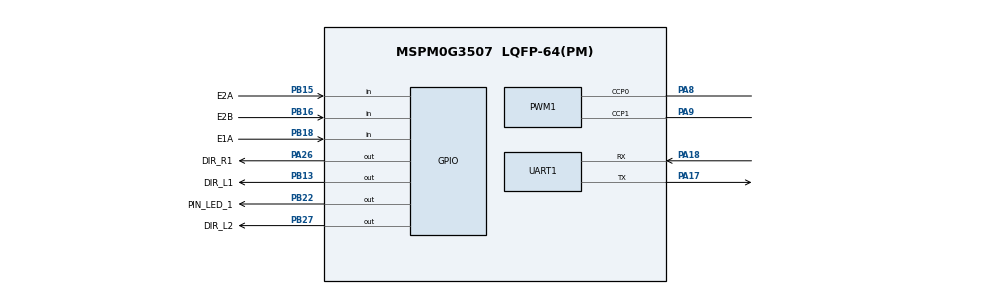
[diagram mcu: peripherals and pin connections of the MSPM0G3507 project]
/**
 * These arguments were used when this file was generated. They will be automatically applied on subsequent loads
 * via the GUI or CLI. Run CLI with '--help' for additional information on how to override these arguments.
 * @cliArgs --device "MSPM0G350X" --part "Default" --package "LQFP-64(PM)" --product "mspm0_sdk@2.05.01.00"
 * @v2CliArgs --device "MSPM0G3507" --package "LQFP-64(PM)" --product "mspm0_sdk@2.05.01.00"
 * @versions {"tool":"1.24.0+4110"}
 */

/**
 * Import the modules used in this configuration.
 */
const GPIO   = scripting.addModule("/ti/driverlib/GPIO", {}, false);
const GPIO1  = GPIO.addInstance();
const GPIO2  = GPIO.addInstance();
const GPIO3  = GPIO.addInstance();
const GPIO4  = GPIO.addInstance();
const GPIO5  = GPIO.addInstance();
const GPIO6  = GPIO.addInstance();
const PWM    = scripting.addModule("/ti/driverlib/PWM", {}, false);
const PWM1   = PWM.addInstance();
const SYSCTL = scripting.addModule("/ti/driverlib/SYSCTL");
const TIMER  = scripting.addModule("/ti/driverlib/TIMER", {}, false);
const TIMER1 = TIMER.addInstance();
const TIMER2 = TIMER.addInstance();
const UART   = scripting.addModule("/ti/driverlib/UART", {}, false);
const UART1  = UART.addInstance();

/**
 * Write custom configuration values to the imported modules.
 */
const divider6       = system.clockTree["PLL_CLK2X_DIV"];
divider6.divideValue = 4;

const divider7       = system.clockTree["PLL_PDIV"];
divider7.divideValue = 2;

const divider9       = system.clockTree["UDIV"];
divider9.divideValue = 2;

const multiplier2         = system.clockTree["PLL_QDIV"];
multiplier2.multiplyValue = 10;

const mux8       = system.clockTree["HSCLKMUX"];
mux8.inputSelect = "HSCLKMUX_SYSPLL2X";

GPIO1.$name                         = "GPIO_DIRS";
GPIO1.associatedPins.create(4);
GPIO1.associatedPins[0].$name       = "DIR_L1";
GPIO1.associatedPins[0].pin.$assign = "PB13";
GPIO1.associatedPins[1].$name       = "DIR_L2";
GPIO1.associatedPins[1].pin.$assign = "PB27";
GPIO1.associatedPins[2].$name       = "DIR_R1";
GPIO1.associatedPins[2].pin.$assign = "PA26";
GPIO1.associatedPins[3].$name       = "PIN_R2";

const Board = scripting.addModule("/ti/driverlib/Board", {}, false);

GPIO2.$name                         = "GPIO_LEDS";
GPIO2.associatedPins[0].$name       = "PIN_LED_1";
GPIO2.associatedPins[0].pin.$assign = "PB22";

GPIO3.$name                              = "GPIO_GREY_SENSOR";
GPIO3.associatedPins.create(7);
GPIO3.associatedPins[0].$name            = "L3";
GPIO3.associatedPins[0].direction        = "INPUT";
GPIO3.associatedPins[0].internalResistor = "PULL_UP";
GPIO3.associatedPins[1].$name            = "L2";
GPIO3.associatedPins[1].direction        = "INPUT";
GPIO3.associatedPins[1].internalResistor = "PULL_UP";
GPIO3.associatedPins[2].$name            = "L1";
GPIO3.associatedPins[2].direction        = "INPUT";
GPIO3.associatedPins[2].internalResistor = "PULL_UP";
GPIO3.associatedPins[3].$name            = "M";
GPIO3.associatedPins[3].direction        = "INPUT";
GPIO3.associatedPins[3].internalResistor = "PULL_UP";
GPIO3.associatedPins[4].$name            = "R1";
GPIO3.associatedPins[4].direction        = "INPUT";
GPIO3.associatedPins[4].internalResistor = "PULL_UP";
GPIO3.associatedPins[5].$name            = "R2";
GPIO3.associatedPins[5].internalResistor = "PULL_UP";
GPIO3.associatedPins[6].$name            = "R3";
GPIO3.associatedPins[6].direction        = "INPUT";
GPIO3.associatedPins[6].internalResistor = "PULL_UP";

GPIO4.$name                               = "ENCODERA";
GPIO4.associatedPins.create(2);
GPIO4.associatedPins[0].direction         = "INPUT";
GPIO4.associatedPins[0].internalResistor  = "PULL_DOWN";
GPIO4.associatedPins[0].interruptEn       = true;
GPIO4.associatedPins[0].interruptPriority = "0";
GPIO4.associatedPins[0].polarity          = "RISE";
GPIO4.associatedPins[0].assignedPort      = "PORTB";
GPIO4.associatedPins[0].assignedPin       = "18";
GPIO4.associatedPins[0].$name             = "E1A";
GPIO4.associatedPins[0].pin.$assign       = "PB18";
GPIO4.associatedPins[1].direction         = "INPUT";
GPIO4.associatedPins[1].internalResistor  = "PULL_DOWN";
GPIO4.associatedPins[1].assignedPort      = "PORTB";
GPIO4.associatedPins[1].assignedPin       = "17";
GPIO4.associatedPins[1].$name             = "E1B";
GPIO4.associatedPins[1].interruptEn       = true;
GPIO4.associatedPins[1].interruptPriority = "0";
GPIO4.associatedPins[1].polarity          = "RISE";

GPIO5.$name                               = "ENCODERB";
GPIO5.associatedPins.create(2);
GPIO5.associatedPins[0].$name             = "E2A";
GPIO5.associatedPins[0].direction         = "INPUT";
GPIO5.associatedPins[0].interruptEn       = true;
GPIO5.associatedPins[0].interruptPriority = "0";
GPIO5.associatedPins[0].polarity          = "RISE";
GPIO5.associatedPins[0].internalResistor  = "PULL_DOWN";
GPIO5.associatedPins[0].assignedPort      = "PORTB";
GPIO5.associatedPins[0].assignedPin       = "15";
GPIO5.associatedPins[0].pin.$assign       = "PB15";
GPIO5.associatedPins[1].$name             = "E2B";
GPIO5.associatedPins[1].direction         = "INPUT";
GPIO5.associatedPins[1].interruptEn       = true;
GPIO5.associatedPins[1].interruptPriority = "0";
GPIO5.associatedPins[1].polarity          = "RISE";
GPIO5.associatedPins[1].internalResistor  = "PULL_DOWN";
GPIO5.associatedPins[1].assignedPort      = "PORTB";
GPIO5.associatedPins[1].assignedPin       = "16";
GPIO5.associatedPins[1].pin.$assign       = "PB16";

GPIO6.$name                               = "KEYS";
GPIO6.associatedPins.create(4);
GPIO6.associatedPins[0].$name             = "KEY1";
GPIO6.associatedPins[0].direction         = "INPUT";
GPIO6.associatedPins[0].interruptEn       = true;
GPIO6.associatedPins[0].interruptPriority = "0";
GPIO6.associatedPins[0].internalResistor  = "PULL_UP";
GPIO6.associatedPins[0].assignedPort      = "PORTB";
GPIO6.associatedPins[0].assignedPin       = "14";
GPIO6.associatedPins[0].polarity          = "RISE_FALL";
GPIO6.associatedPins[1].$name             = "KEY2";
GPIO6.associatedPins[1].direction         = "INPUT";
GPIO6.associatedPins[1].internalResistor  = "PULL_UP";
GPIO6.associatedPins[1].assignedPort      = "PORTB";
GPIO6.associatedPins[1].assignedPin       = "19";
GPIO6.associatedPins[1].interruptEn       = true;
GPIO6.associatedPins[1].interruptPriority = "0";
GPIO6.associatedPins[1].polarity          = "RISE_FALL";
GPIO6.associatedPins[2].$name             = "KEY3";
GPIO6.associatedPins[2].direction         = "INPUT";
GPIO6.associatedPins[2].internalResistor  = "PULL_UP";
GPIO6.associatedPins[2].assignedPort      = "PORTB";
GPIO6.associatedPins[2].assignedPin       = "20";
GPIO6.associatedPins[2].interruptEn       = true;
GPIO6.associatedPins[2].interruptPriority = "0";
GPIO6.associatedPins[2].polarity          = "RISE_FALL";
GPIO6.associatedPins[3].$name             = "KEY4";
GPIO6.associatedPins[3].direction         = "INPUT";
GPIO6.associatedPins[3].internalResistor  = "PULL_UP";
GPIO6.associatedPins[3].interruptEn       = true;
GPIO6.associatedPins[3].interruptPriority = "0";
GPIO6.associatedPins[3].polarity          = "RISE_FALL";

PWM1.$name                              = "PWM_ENCODER";
PWM1.timerCount                         = 2000;
PWM1.peripheral.$assign                 = "TIMA0";
PWM1.peripheral.ccp0Pin.$assign         = "PA8";
PWM1.peripheral.ccp1Pin.$assign         = "PA9";
PWM1.PWM_CHANNEL_0.$name                = "ti_driverlib_pwm_PWMTimerCC2";
PWM1.PWM_CHANNEL_0.dutyCycle            = 50;
PWM1.PWM_CHANNEL_1.$name                = "ti_driverlib_pwm_PWMTimerCC3";
PWM1.PWM_CHANNEL_1.dutyCycle            = 50;
PWM1.ccp0PinConfig.direction            = scripting.forceWrite("OUTPUT");
PWM1.ccp0PinConfig.hideOutputInversion  = scripting.forceWrite(false);
PWM1.ccp0PinConfig.onlyInternalResistor = scripting.forceWrite(false);
PWM1.ccp0PinConfig.passedPeripheralType = scripting.forceWrite("Digital");
PWM1.ccp0PinConfig.$name                = "ti_driverlib_gpio_GPIOPinGeneric4";
PWM1.ccp1PinConfig.direction            = scripting.forceWrite("OUTPUT");
PWM1.ccp1PinConfig.hideOutputInversion  = scripting.forceWrite(false);
PWM1.ccp1PinConfig.onlyInternalResistor = scripting.forceWrite(false);
PWM1.ccp1PinConfig.passedPeripheralType = scripting.forceWrite("Digital");
PWM1.ccp1PinConfig.$name                = "ti_driverlib_gpio_GPIOPinGeneric5";

SYSCTL.forceDefaultClkConfig = true;
SYSCTL.clockTreeEn           = true;

TIMER1.$name              = "TIMER_LOGIC";
TIMER1.timerClkDiv        = 8;
TIMER1.interrupts         = ["ZERO"];
TIMER1.timerClkPrescale   = 10;
TIMER1.timerPeriod        = "10ms";
TIMER1.timerStartTimer    = true;
TIMER1.timerMode          = "PERIODIC";
TIMER1.interruptPriority  = "0";
TIMER1.peripheral.$assign = "TIMA1";

TIMER2.$name           = "TIMER_BUTTON";
TIMER2.timerPeriod     = "1ms";
TIMER2.timerStartTimer = true;
TIMER2.interrupts      = ["ZERO"];
TIMER2.timerMode       = "PERIODIC";

UART1.targetBaudRate                   = 115200;
UART1.enabledInterrupts                = ["RX"];
UART1.$name                            = "UART_TJC";
UART1.peripheral.$assign               = "UART1";
UART1.peripheral.rxPin.$assign         = "PA18";
UART1.peripheral.txPin.$assign         = "PA17";
UART1.txPinConfig.direction            = scripting.forceWrite("OUTPUT");
UART1.txPinConfig.hideOutputInversion  = scripting.forceWrite(false);
UART1.txPinConfig.onlyInternalResistor = scripting.forceWrite(false);
UART1.txPinConfig.passedPeripheralType = scripting.forceWrite("Digital");
UART1.txPinConfig.$name                = "ti_driverlib_gpio_GPIOPinGeneric0";
UART1.rxPinConfig.hideOutputInversion  = scripting.forceWrite(false);
UART1.rxPinConfig.onlyInternalResistor = scripting.forceWrite(false);
UART1.rxPinConfig.passedPeripheralType = scripting.forceWrite("Digital");
UART1.rxPinConfig.$name                = "ti_driverlib_gpio_GPIOPinGeneric1";

/**
 * Pinmux solution for unlocked pins/peripherals. This ensures that minor changes to the automatic solver in a future
 * version of the tool will not impact the pinmux you originally saw.  These lines can be completely deleted in order to
 * re-solve from scratch.
 */
GPIO1.associatedPins[3].pin.$suggestSolution = "PB21";
Board.peripheral.$suggestSolution            = "DEBUGSS";
Board.peripheral.swclkPin.$suggestSolution   = "PA20";
Board.peripheral.swdioPin.$suggestSolution   = "PA19";
GPIO3.associatedPins[0].pin.$suggestSolution = "PA22";
GPIO3.associatedPins[1].pin.$suggestSolution = "PA21";
GPIO3.associatedPins[2].pin.$suggestSolution = "PA16";
GPIO3.associatedPins[3].pin.$suggestSolution = "PA15";
GPIO3.associatedPins[4].pin.$suggestSolution = "PA14";
GPIO3.associatedPins[5].pin.$suggestSolution = "PB23";
GPIO3.associatedPins[6].pin.$suggestSolution = "PA13";
GPIO4.associatedPins[1].pin.$suggestSolution = "PB17";
GPIO6.associatedPins[0].pin.$suggestSolution = "PB14";
GPIO6.associatedPins[1].pin.$suggestSolution = "PB19";
GPIO6.associatedPins[2].pin.$suggestSolution = "PB20";
GPIO6.associatedPins[3].pin.$suggestSolution = "PA12";
TIMER2.peripheral.$suggestSolution           = "TIMG0";
